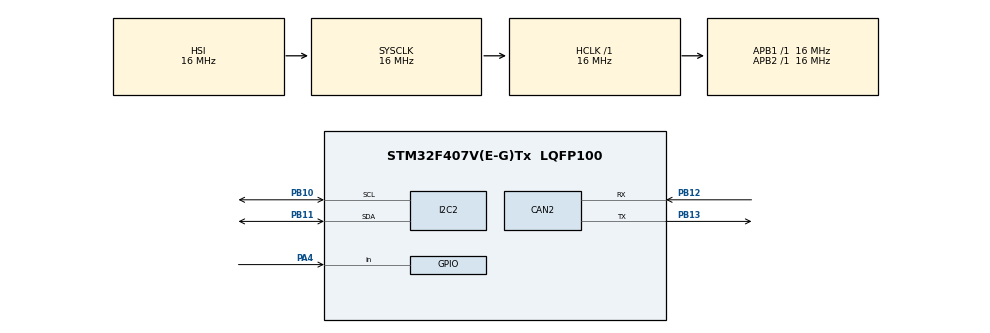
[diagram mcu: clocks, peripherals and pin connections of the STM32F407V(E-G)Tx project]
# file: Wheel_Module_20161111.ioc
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CAN2.CalculateTimeBit=3000
CAN2.CalculateTimeQuantum=1000.0
Mcu.Family=STM32F4
Mcu.Name=STM32F407V(E-G)Tx
Mcu.Package=LQFP100
NVIC.PriorityGroup=NVIC_PRIORITYGROUP_4
PA13.Mode=Serial_Wire
PA13.Signal=SYS_JTMS-SWDIO
PA14.Mode=Serial_Wire
PA14.Signal=SYS_JTCK-SWCLK
PA4.Signal=GPIO_Input
PA8.Signal=S_TIM1_CH1
PB10.Mode=I2C
PB10.Signal=I2C2_SCL
PB11.Mode=I2C
PB11.Signal=I2C2_SDA
PB12.Mode=Slave
PB12.Signal=CAN2_RX
PB13.Mode=Slave
PB13.Signal=CAN2_TX
PC14-OSC32_IN.Signal=RCC_OSC32_IN
PH0-OSC_IN.Signal=RCC_OSC_IN
ProjectManager.HeapSize=0x200
ProjectManager.StackSize=0x400
ProjectManager.TargetToolchain=EWARM
RCC.AHBFreq_Value=16000000
RCC.APB1Freq_Value=16000000
RCC.APB2Freq_Value=16000000
RCC.CortexFreq_Value=16000000
RCC.HSE_VALUE=25000000
RCC.HSI_VALUE=16000000
RCC.LSE_VALUE=32768
RCC.SYSCLKFreq_VALUE=16000000
RCC.VCOOutputFreq_Value=192000000
SH.S_TIM1_CH1.0=TIM1_CH1
board=Wheel_Module_20161111

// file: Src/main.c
/**
  ******************************************************************************
  * File Name          : main.c
  * Description        : Main program body
  ******************************************************************************
  *
  * COPYRIGHT(c) 2016 STMicroelectronics
  *
  * Redistribution and use in source and binary forms, with or without modification,
  * are permitted provided that the following conditions are met:
  *   1. Redistributions of source code must retain the above copyright notice,
  *      this list of conditions and the following disclaimer.
  *   2. Redistributions in binary form must reproduce the above copyright notice,
  *      this list of conditions and the following disclaimer in the documentation
  *      and/or other materials provided with the distribution.
  *   3. Neither the name of STMicroelectronics nor the names of its contributors
  *      may be used to endorse or promote products derived from this software
  *      without specific prior written permission.
  *
  * THIS SOFTWARE IS PROVIDED BY THE COPYRIGHT HOLDERS AND CONTRIBUTORS "AS IS"
  * AND ANY EXPRESS OR IMPLIED WARRANTIES, INCLUDING, BUT NOT LIMITED TO, THE
  * IMPLIED WARRANTIES OF MERCHANTABILITY AND FITNESS FOR A PARTICULAR PURPOSE ARE
  * DISCLAIMED. IN NO EVENT SHALL THE COPYRIGHT HOLDER OR CONTRIBUTORS BE LIABLE
  * FOR ANY DIRECT, INDIRECT, INCIDENTAL, SPECIAL, EXEMPLARY, OR CONSEQUENTIAL
  * DAMAGES (INCLUDING, BUT NOT LIMITED TO, PROCUREMENT OF SUBSTITUTE GOODS OR
  * SERVICES; LOSS OF USE, DATA, OR PROFITS; OR BUSINESS INTERRUPTION) HOWEVER
  * CAUSED AND ON ANY THEORY OF LIABILITY, WHETHER IN CONTRACT, STRICT LIABILITY,
  * OR TORT (INCLUDING NEGLIGENCE OR OTHERWISE) ARISING IN ANY WAY OUT OF THE USE
  * OF THIS SOFTWARE, EVEN IF ADVISED OF THE POSSIBILITY OF SUCH DAMAGE.
  *
  ******************************************************************************
  */
#include "main.h"
#include "stm32f4xx_hal.h"

/* USER CODE BEGIN Includes */
	//need to initialize the temperature sensor

	//need to initialize the wheel speed sensor

	//eventually will have to initialize the potentiometer

/* USER CODE END Includes */

CAN_HandleTypeDef hcan2;

I2C_HandleTypeDef hi2c2;

/* USER CODE BEGIN PV */
/* Private variables ---------------------------------------------------------*/

/* USER CODE END PV */

void SystemClock_Config(void);
void Error_Handler(void);
static void MX_GPIO_Init(void);
static void MX_CAN2_Init(void);
static void MX_I2C2_Init(void);

/* USER CODE BEGIN PFP */
/* Private function prototypes -----------------------------------------------*/

/* USER CODE END PFP */

int main(void)
{

  /* USER CODE BEGIN 1 */
	init_temp_sensor_trim();
	//need to define init_value look at temp.c
	init_temp_sensor_16bit(init_value);
	//call temperature sensor initialization function

  /* USER CODE END 1 */

  /* MCU Configuration----------------------------------------------------------*/

  /* Reset of all peripherals, Initializes the Flash interface and the Systick. */
  HAL_Init();

  /* Configure the system clock */
  SystemClock_Config();

  /* Initialize all configured peripherals */
  MX_GPIO_Init();
  MX_CAN2_Init();
  MX_I2C2_Init();

  /* Infinite loop */
  /* USER CODE BEGIN WHILE */
  int temp_flag = 0;
  int speed_flag = 0;
  int pot_flag = 0;
  while (1)
  {
  /* USER CODE END WHILE */
	  //need to get time......

	  //if a multiple of this amount of time do temperature sensor
	  //want this done every 10th of a second
	  temp_flag = temp_main();
	  //if a multiple of this amount of time do wheel speed sensor
	  //every 10th of a second
	  speed_flag = Wheel_Speed_main();
	  //if a multiple of this amount of time do potentiometer
	  pot_flag = pot_main();

	  //error checking
	  //check the flags for these functions

	  //system pause
  }

}

/** System Clock Configuration
*/
void SystemClock_Config(void)
{

  RCC_OscInitTypeDef RCC_OscInitStruct;
  RCC_ClkInitTypeDef RCC_ClkInitStruct;

    /**Configure the main internal regulator output voltage
    */
  __HAL_RCC_PWR_CLK_ENABLE();

  __HAL_PWR_VOLTAGESCALING_CONFIG(PWR_REGULATOR_VOLTAGE_SCALE1);

    /**Initializes the CPU, AHB and APB busses clocks
    */
  RCC_OscInitStruct.OscillatorType = RCC_OSCILLATORTYPE_HSI;
  RCC_OscInitStruct.HSIState = RCC_HSI_ON;
  RCC_OscInitStruct.HSICalibrationValue = 16;
  RCC_OscInitStruct.PLL.PLLState = RCC_PLL_NONE;
  if (HAL_RCC_OscConfig(&RCC_OscInitStruct) != HAL_OK)
  {
    Error_Handler();
  }

    /**Initializes the CPU, AHB and APB busses clocks
    */
  RCC_ClkInitStruct.ClockType = RCC_CLOCKTYPE_HCLK|RCC_CLOCKTYPE_SYSCLK
                              |RCC_CLOCKTYPE_PCLK1|RCC_CLOCKTYPE_PCLK2;
  RCC_ClkInitStruct.SYSCLKSource = RCC_SYSCLKSOURCE_HSI;
  RCC_ClkInitStruct.AHBCLKDivider = RCC_SYSCLK_DIV1;
  RCC_ClkInitStruct.APB1CLKDivider = RCC_HCLK_DIV1;
  RCC_ClkInitStruct.APB2CLKDivider = RCC_HCLK_DIV1;

  if (HAL_RCC_ClockConfig(&RCC_ClkInitStruct, FLASH_LATENCY_0) != HAL_OK)
  {
    Error_Handler();
  }

    /**Configure the Systick interrupt time
    */
  HAL_SYSTICK_Config(HAL_RCC_GetHCLKFreq()/1000);

    /**Configure the Systick
    */
  HAL_SYSTICK_CLKSourceConfig(SYSTICK_CLKSOURCE_HCLK);

  /* SysTick_IRQn interrupt configuration */
  HAL_NVIC_SetPriority(SysTick_IRQn, 0, 0);
}

/* CAN2 init function */
static void MX_CAN2_Init(void)
{

  hcan2.Instance = CAN2;
  hcan2.Init.Prescaler = 16;
  hcan2.Init.Mode = CAN_MODE_NORMAL;
  hcan2.Init.SJW = CAN_SJW_1TQ;
  hcan2.Init.BS1 = CAN_BS1_1TQ;
  hcan2.Init.BS2 = CAN_BS2_1TQ;
  hcan2.Init.TTCM = DISABLE;
  hcan2.Init.ABOM = DISABLE;
  hcan2.Init.AWUM = DISABLE;
  hcan2.Init.NART = DISABLE;
  hcan2.Init.RFLM = DISABLE;
  hcan2.Init.TXFP = DISABLE;
  if (HAL_CAN_Init(&hcan2) != HAL_OK)
  {
    Error_Handler();
  }

}

/* I2C2 init function */
static void MX_I2C2_Init(void)
{

  hi2c2.Instance = I2C2;
  hi2c2.Init.ClockSpeed = 100000;
  hi2c2.Init.DutyCycle = I2C_DUTYCYCLE_2;
  hi2c2.Init.OwnAddress1 = 0;
  hi2c2.Init.AddressingMode = I2C_ADDRESSINGMODE_7BIT;
  hi2c2.Init.DualAddressMode = I2C_DUALADDRESS_DISABLE;
  hi2c2.Init.OwnAddress2 = 0;
  hi2c2.Init.GeneralCallMode = I2C_GENERALCALL_DISABLE;
  hi2c2.Init.NoStretchMode = I2C_NOSTRETCH_DISABLE;
  if (HAL_I2C_Init(&hi2c2) != HAL_OK)
  {
    Error_Handler();
  }

}

/** Configure pins as
        * Analog
        * Input
        * Output
        * EVENT_OUT
        * EXTI
     PA8   ------> S_TIM1_CH1
*/
static void MX_GPIO_Init(void)
{

  GPIO_InitTypeDef GPIO_InitStruct;

  /* GPIO Ports Clock Enable */
  __HAL_RCC_GPIOC_CLK_ENABLE();
  __HAL_RCC_GPIOH_CLK_ENABLE();
  __HAL_RCC_GPIOA_CLK_ENABLE();
  __HAL_RCC_GPIOB_CLK_ENABLE();

  /*Configure GPIO pin : PA4 */
  GPIO_InitStruct.Pin = GPIO_PIN_4;
  GPIO_InitStruct.Mode = GPIO_MODE_INPUT;
  GPIO_InitStruct.Pull = GPIO_NOPULL;
  HAL_GPIO_Init(GPIOA, &GPIO_InitStruct);

  /*Configure GPIO pin : PA8 */
  GPIO_InitStruct.Pin = GPIO_PIN_8;
  GPIO_InitStruct.Mode = GPIO_MODE_AF_PP;
  GPIO_InitStruct.Pull = GPIO_NOPULL;
  GPIO_InitStruct.Speed = GPIO_SPEED_FREQ_LOW;
  GPIO_InitStruct.Alternate = GPIO_AF1_TIM1;
  HAL_GPIO_Init(GPIOA, &GPIO_InitStruct);

}

void Error_Handler(void)
{
  while(1)
  {
  }
}

/************************ (C) COPYRIGHT STMicroelectronics *****END OF FILE****/
